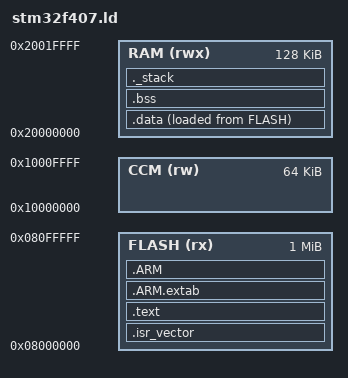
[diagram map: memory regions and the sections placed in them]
/* STM32F407VGT6: 1024K flash, 128K SRAM (+64K CCM, unused here). */
MEMORY
{
  FLASH (rx)  : ORIGIN = 0x08000000, LENGTH = 1024K
  RAM   (rwx) : ORIGIN = 0x20000000, LENGTH = 128K
  CCM   (rw)  : ORIGIN = 0x10000000, LENGTH = 64K
}

_estack = ORIGIN(RAM) + LENGTH(RAM);
_min_stack = 0x1000;

SECTIONS
{
  .isr_vector : { KEEP(*(.isr_vector)) } >FLASH

  .text :
  {
    *(.text .text.*)
    *(.rodata .rodata.*)
    *(.glue_7) *(.glue_7t)
    KEEP(*(.init)) KEEP(*(.fini))
    . = ALIGN(4);
  } >FLASH

  .ARM.extab : { *(.ARM.extab* .gnu.linkonce.armextab.*) } >FLASH
  .ARM :
  {
    __exidx_start = .;
    *(.ARM.exidx*)
    __exidx_end = .;
  } >FLASH

  .data :
  {
    . = ALIGN(4);
    _sdata = .;
    *(.data .data.*)
    . = ALIGN(4);
    _edata = .;
  } >RAM AT> FLASH

  _sidata = LOADADDR(.data);

  .bss :
  {
    . = ALIGN(4);
    _sbss = .;
    *(.bss .bss.*)
    *(COMMON)
    . = ALIGN(4);
    _ebss = .;
  } >RAM

  /* Reserve stack so a link that overflows RAM fails here rather than at
     3 a.m. on an engine. */
  ._stack (NOLOAD) :
  {
    . = ALIGN(8);
    . = . + _min_stack;
    . = ALIGN(8);
  } >RAM

  .ARM.attributes 0 : { *(.ARM.attributes) }
}
